# VLCDJ_L3Interconnect register map
Vendor: Texas Instruments
Peripheral module from a debugger description file (folder omap4430).
Registers are 32-bit, access per field, reset 0x0 unless marked. A register's access mark holds for its fields unless they carry their own. Offsets are as the file gives them; lines under a group give offsets from that group; [hi:lo] are bit positions; {n}, {i} and the like mark numbered series; 'fields as' and 'values as' point back to an identical list; <NAME> marks a mode.

## VLCDJ_L3Interconnect
0x00 VLCDJ_REVISION ro reset not defined — IP revision
  [31:0] REVISION — IP Revision
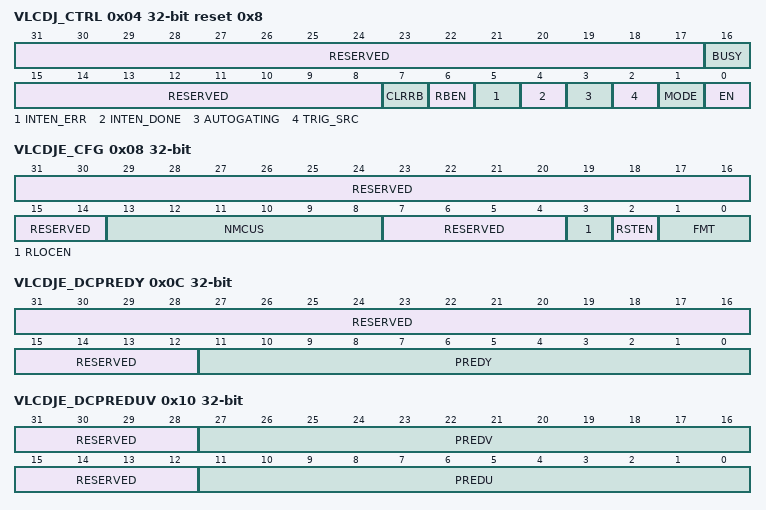
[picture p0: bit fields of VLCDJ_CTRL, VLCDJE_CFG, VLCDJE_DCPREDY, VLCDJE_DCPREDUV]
0x04 VLCDJ_CTRL reset 0x8 — Controls common to encoding and decoding
  [31:17] RESERVED ro — Read returns 0.
  [16] BUSY ro — Idle/busy status 0: Idle 1: Busy
  [15:8] RESERVED ro — Read returns 0.
  [7] CLRRB wo — Write only; read returns 0.
  [6] RBEN rw — Enable RB signaling.
  [5] INTEN_ERR rw — Interrupt enable for decode error 0: No interrupt generated on decode error 1: Interrupt generated on decode error
  [4] INTEN_DONE rw — Interrupt enable for task completion. DONE_VLCD is not gated by this and is always asserted at task completion. 0: No interrupt generated on task completion 1: Interrupt generated on task completion
  [3] AUTOGATING rw — Internal clock gating on OCP clock and functional clock 0: Clocks are free-running. 1: Clocks are gated off in sub-blocks that are not required for operation.
  [2] TRIG_SRC rw — Which mechanism starts VLCDJ operation 0: MMR write to VLCDJ_CTRL.EN 1: Hardware start signal
  [1] MODE rw — 0: Encode 1: Decode
  [0] EN wo — Module enable by software (write-only, read returns 0). When TRIG_SRC = 0 and BUSY = 0, set this field to 1 to start VLCDJ. When TRIG_SRC = 1, writes to this field are ignored. Setting TRIG_SRC = 0 and EN = 1 on the same register write is recognized.
0x08 VLCDJE_CFG — Encode configuration
  [31:14] RESERVED ro — Read returns 0.
  [13:8] NMCUS rw — Number of MCUs (FMT = 0, 1) or blocks (FMT = 2) to encode 0: 1 MCU 1: 2 MCUs, etc.
  [7:4] RESERVED ro — Read returns 0.
  [3] RLOCEN rw — Restart marker location recording enable 0: Restart marker location recording disabled 1: Restart marker location recording enabled
  [2] RSTEN rw — Restart marker insertion enable 0: Restart marker insertion disabled 1: Restart marker insertion enabled
  [1:0] FMT rw — 0: YUV4:2:0 1: YUV4:2:2 2 : Sequential blocks
0x0C VLCDJE_DCPREDY — Encode DC predictor for Y
  [31:12] RESERVED ro — Read returns 0.
  [11:0] PREDY rw — DC predictor for Y
0x10 VLCDJE_DCPREDUV — Encode DC predictor for U and V
  [31:28] RESERVED ro — Read returns 0.
  [27:16] PREDV rw — DC predictor for V
  [15:12] RESERVED ro — Read returns 0.
  [11:0] PREDU rw — DC predictor for U
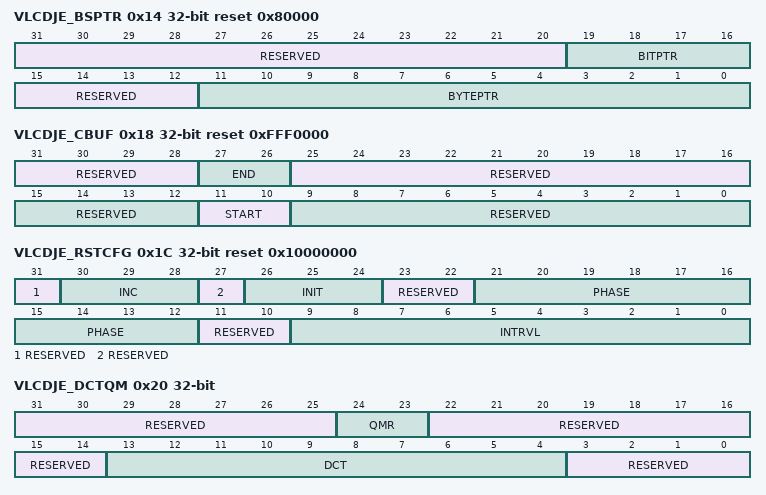
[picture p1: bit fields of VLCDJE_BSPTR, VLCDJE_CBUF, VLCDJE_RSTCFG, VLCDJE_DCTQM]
0x14 VLCDJE_BSPTR reset 0x80000 — Encode bitstream pointer
  [31:20] RESERVED ro — Read returns 0.
  [19:16] BITPTR rw — Bit pointer, 1..8, indicates number of available bits
  [15:12] RESERVED ro — Read returns 0.
  [11:0] BYTEPTR rw — Byte pointer (to BSMEM)
0x18 VLCDJE_CBUF access not given reset 0xFFF0000 — Encode bitstream circular buffer
  [31:28] RESERVED ro — Read returns 0.
  [27:26] END rw — Ending quarter (1KB each unit) of bitstream buffer. Software can write a byte address into the upper 16 bits of the register.
  [25:16] RESERVED — Read returns 0x3FF. (access R; returns 1s)
  [15:12] RESERVED ro — Read returns 0.
  [11:10] START rw — Starting quarter (1KB each unit) of bitstream buffer. Software can write a byte address to the lower 16 bits of the register.
  [9:0] RESERVED ro — Read returns 0.
0x1C VLCDJE_RSTCFG reset 0x10000000 — Encode restart marker configuration
  [31] RESERVED ro — Read returns 0.
  [30:28] INC rw — Restart count increment value
  [27] RESERVED ro — Read returns 0.
  [26:24] INIT rw — Restart marker initial count
  [23:22] RESERVED ro — Read returns 0.
  [21:12] PHASE rw — MCU count within the interval
  [11:10] RESERVED ro — Read returns 0.
  [9:0] INTRVL rw — Restart interval (in MCUs)
0x20 VLCDJE_DCTQM — Encode DCT coefficient and quantizer matrix pointers
  [31:25] RESERVED ro — Read returns 0.
  [24:23] QMR rw — Quarter (128 bytes/unit) of quantization matrix reciprocal. Software can write a byte address to the upper 16 bits of the register.
  [22:14] RESERVED ro — Read returns 0.
  [13:4] DCT rw — 128-bit/word address of DCT coefficients. Software can write a byte address to the lower 16 bits of the register.
  [3:0] RESERVED ro — Read returns 0.
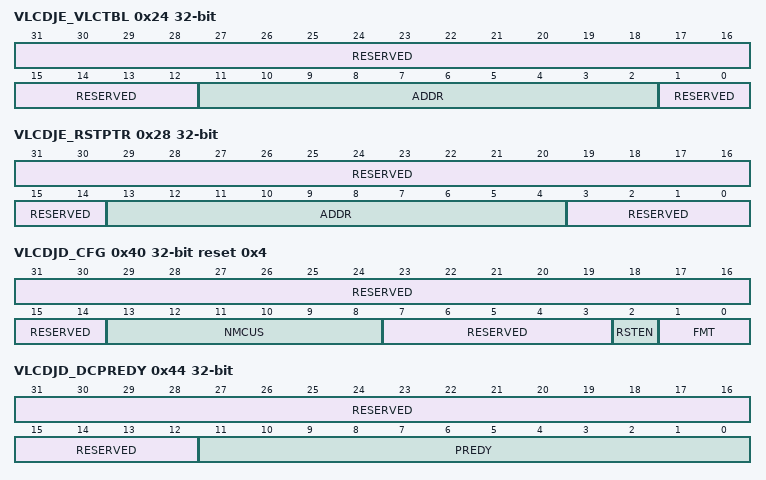
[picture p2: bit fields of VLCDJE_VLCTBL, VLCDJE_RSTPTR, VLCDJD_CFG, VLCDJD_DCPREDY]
0x24 VLCDJE_VLCTBL — Encode Huffman table pointer
  [31:12] RESERVED ro — Read returns 0.
  [11:2] ADDR rw — Encode Huffman table pointer, 32-bit word address. Software can write a byte address into the entire register.
  [1:0] RESERVED ro — Read returns 0.
0x28 VLCDJE_RSTPTR — Encode restart marker locations
  [31:14] RESERVED ro — Read returns 0.
  [13:4] ADDR rw — Pointer to restart marker locations in image buffer, 128-bit/word address Software can write a byte address into the entire register.
  [3:0] RESERVED ro — Read returns 0.
0x2C VLCDJE_RSTOFST rw — SDRAM address to add to encode restart marker locations
  [31:0] OFFSET — SDRAM address of bitstream buffer, to be added to the restart marker locations
0x40 VLCDJD_CFG reset 0x4 — Decode configuration
  [31:14] RESERVED ro — Read returns 0.
  [13:8] NMCUS rw — Number of MCUs (FMT = 0, 1) or blocks (FMT = 2) to decode 0: 1 MCU 1: 2 MCUs, etc.
  [7:3] RESERVED ro — Read returns 0.
  [2] RSTEN rw — Restart marker detection/processing enable 0: Restart marker detection/processing disabled 1: Restart marker detection/processing enabled
  [1:0] FMT rw — 0: YUV4:2:0 1: YUV4:2:2 2: Sequential blocks
0x44 VLCDJD_DCPREDY — Decode DC predictor for Y
  fields as VLCDJE_DCPREDY
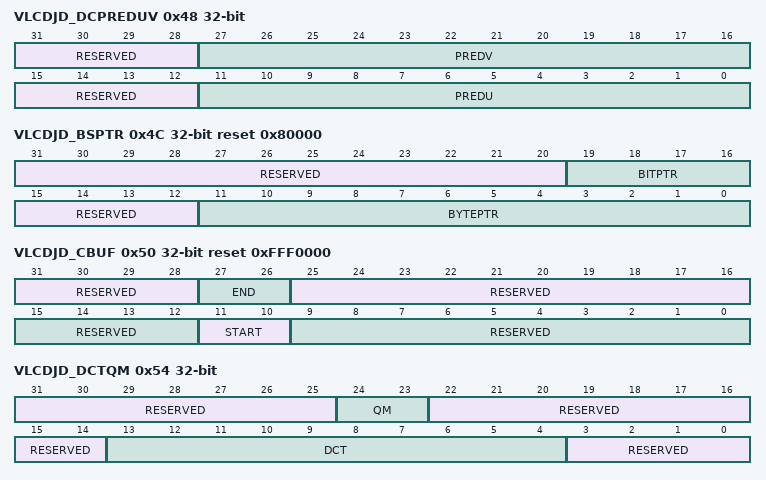
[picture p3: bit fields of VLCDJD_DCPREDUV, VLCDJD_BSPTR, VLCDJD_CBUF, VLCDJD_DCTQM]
0x48 VLCDJD_DCPREDUV — Decode DC predictor for U and V
  fields as VLCDJE_DCPREDUV
0x4C VLCDJD_BSPTR reset 0x80000 — Decode bitstream pointer
  fields as VLCDJE_BSPTR
0x50 VLCDJD_CBUF access not given reset 0xFFF0000 — Decode bitstream circular buffer
  fields as VLCDJE_CBUF
0x54 VLCDJD_DCTQM — Decode DCT coefficient and quantizer matrix pointers
  [31:25] RESERVED ro — Read returns 0.
  [24:23] QM rw — Quarter (128 bytes/unit) of quantization matrix. Software can write a byte address to the upper 16 bits of the register.
  [22:14] RESERVED ro — Read returns 0.
  [13:4] DCT rw — 128-bit/word address of DCT coefficients. Software can write a byte address to the lower 16 bits of the register.
  [3:0] RESERVED ro — Read returns 0.
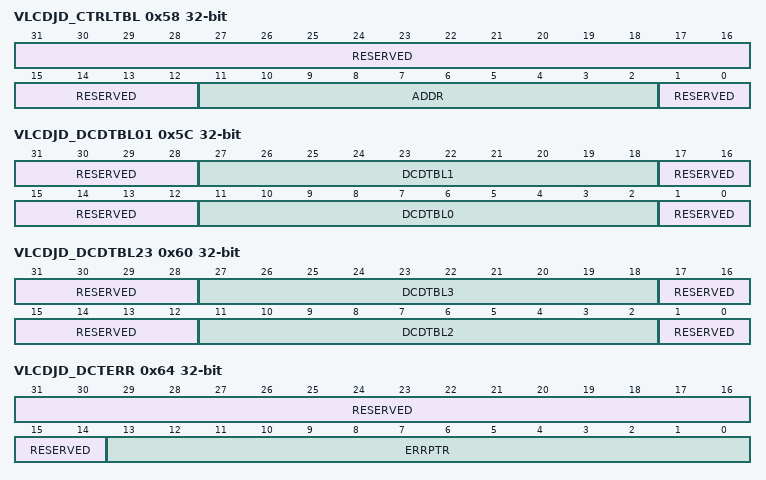
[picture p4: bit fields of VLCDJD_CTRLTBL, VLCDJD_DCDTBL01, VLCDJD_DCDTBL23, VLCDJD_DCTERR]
0x58 VLCDJD_CTRLTBL — Decode control table base
  [31:12] RESERVED ro — Read returns 0.
  [11:2] ADDR rw — Starting address of decode control table, 32-bit word. Software can write a byte address into the entire register.
  [1:0] RESERVED ro — Read returns 0.
0x5C VLCDJD_DCDTBL01 — Decode Huffman tables 0 and 1
  [31:28] RESERVED ro — Read returns 0.
  [27:18] DCDTBL1 rw — Starting byte address of decode table 1, 32-bit word. Software can write a byte address into the lower 16 bits of the register. This is for Luma AC.
  [17:12] RESERVED ro — Read returns 0.
  [11:2] DCDTBL0 rw — Starting byte address of decode table 0, 32-bit word. Software can write a byte address into the lower 16 bits of the register. This is for Luma DC.
  [1:0] RESERVED ro — Read returns 0.
0x60 VLCDJD_DCDTBL23 — Decode Huffman tables 2 and 3
  [31:28] RESERVED ro — Read returns 0.
  [27:18] DCDTBL3 rw — Starting byte address of decode table 3, 32-bit word. Software can write a byte address into the lower 16 bits of the register. This is for Chroma AC.
  [17:12] RESERVED ro — Read returns 0.
  [11:2] DCDTBL2 rw — Starting byte address of decode table 2, 32-bit word. Software can write a byte address into the lower 16 bits of the register. This is for Chroma DC.
  [1:0] RESERVED ro — Read returns 0.
0x64 VLCDJD_DCTERR ro
  [31:14] RESERVED — Read returns 0.
  [13:0] ERRPTR — Byte address pointer to DCT coefficients, near where decode error occurs (read-only)
